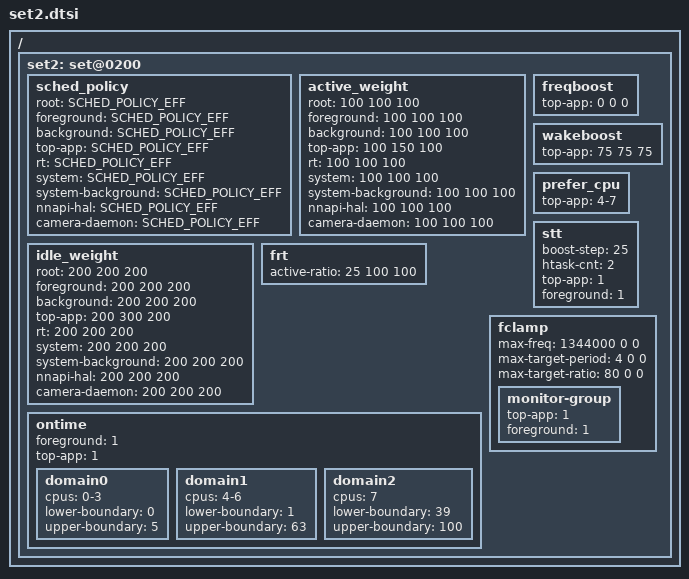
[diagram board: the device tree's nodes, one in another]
/ {
	/* performance mode - default */
	set2: set@0200 {
		/* schedudling policy */
		sched_policy {
			root			= <SCHED_POLICY_EFF>;
			foreground 		= <SCHED_POLICY_EFF>;
			background		= <SCHED_POLICY_EFF>;
			top-app			= <SCHED_POLICY_EFF>;
			rt			= <SCHED_POLICY_EFF>;
			system			= <SCHED_POLICY_EFF>;
			system-background	= <SCHED_POLICY_EFF>;
			nnapi-hal		= <SCHED_POLICY_EFF>;
			camera-daemon		= <SCHED_POLICY_EFF>;
		};

		/* weight (%) applied to active cpu's efficiency */
		active_weight {			/* LIT MED BIG */
			root			= <100 100 100>;
			foreground		= <100 100 100>;
			background		= <100 100 100>;
			top-app			= <100 150 100>;
			rt			= <100 100 100>;
			system			= <100 100 100>;
			system-background	= <100 100 100>;
			nnapi-hal		= <100 100 100>;
			camera-daemon		= <100 100 100>;
		};

		/* weight (%) applied to idle cpu's efficiency */
		idle_weight {			/* LIT MED BIG */
			root			= <200 200 200>;
			foreground		= <200 200 200>;
			background		= <200 200 200>;
			top-app			= <200 300 200>;
			rt			= <200 200 200>;
			system			= <200 200 200>;
			system-background	= <200 200 200>;
			nnapi-hal		= <200 200 200>;
			camera-daemon		= <200 200 200>;
		};

		/* Boosting margin applied to frequency selection */
		freqboost {			/* LIT MED BIG */
			top-app			= <  0   0   0>;
		};

		/* Boosting margin for waking up task */
		wakeboost {			/* LIT MED BIG */
			top-app			= < 75  75  75>;
		};

		frt {	   	     		/* LIT MED BIG */
			active-ratio		= < 25 100 100>;
		};

		/* Ontime Migration */
		ontime {
			foreground 	= <1>;
			top-app		= <1>;

			domain0 {
				cpus = "0-3";
				lower-boundary = <0>;
				upper-boundary = <5>;
			};
			domain1 {
				cpus = "4-6";
				lower-boundary = <1>;
				upper-boundary = <63>;
			};
			domain2 {
				cpus = "7";
				lower-boundary = <39>;
				upper-boundary = <100>;
			};
		};

		prefer_cpu {
			top-app = "4-7";
		};

		stt {
			boost-step		= <25>;
			htask-cnt		= <2>;
			top-app			= <1>;
			foreground		= <1>;
		};

		fclamp {
			max-freq          = < 1344000       0       0>;
			max-target-period = <       4       0       0>;
			max-target-ratio  = <      80       0       0>;

			monitor-group {
				top-app         = <1>;
				foreground      = <1>;
			};
		};
	};
};
